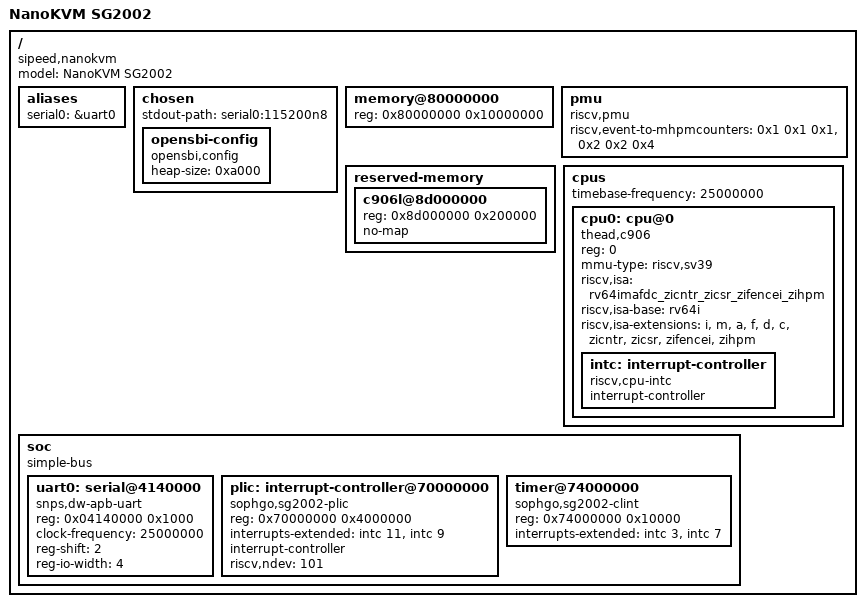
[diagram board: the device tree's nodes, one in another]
// SPDX-License-Identifier: (BSD-2-Clause OR MIT)
// M-mode hardware description: Linux 7.2.9 sg2002.dtsi/cv180x-cpus.dtsi
// and pinned Sipeed FSBL/UART data; independent of NanoKVM board wiring.
/dts-v1/;
/ {
	model = "NanoKVM SG2002";
	compatible = "sipeed,nanokvm", "sophgo,sg2002";
	#address-cells = <1>;
	#size-cells = <1>;
	aliases { serial0 = &uart0; };
	chosen {
		stdout-path = "serial0:115200n8";
		opensbi-config {
			compatible = "opensbi,config";
			heap-size = <0xa000>;
		};
	};
	memory@80000000 {
		device_type = "memory";
		reg = <0x80000000 0x10000000>;
	};
	pmu {
		compatible = "riscv,pmu";
		// SBI 3.0 event-info requires explicit fixed-counter mappings.
		// Advertise only the architectural mcycle/minstret events.
		riscv,event-to-mhpmcounters = <0x1 0x1 0x1>, <0x2 0x2 0x4>;
	};
	reserved-memory {
		#address-cells = <1>;
		#size-cells = <1>;
		ranges;
		c906l@8d000000 { reg = <0x8d000000 0x200000>; no-map; };
	};
	cpus {
		#address-cells = <1>;
		#size-cells = <0>;
		timebase-frequency = <25000000>;
		cpu0: cpu@0 {
			compatible = "thead,c906", "riscv";
			device_type = "cpu";
			reg = <0>;
			status = "okay";
			mmu-type = "riscv,sv39";
			// C906 draft vector support must never be declared as RVV 1.0.
			riscv,isa = "rv64imafdc_zicntr_zicsr_zifencei_zihpm";
			riscv,isa-base = "rv64i";
			riscv,isa-extensions = "i", "m", "a", "f", "d", "c",
				"zicntr", "zicsr", "zifencei", "zihpm";
			intc: interrupt-controller {
				compatible = "riscv,cpu-intc";
				interrupt-controller;
				#interrupt-cells = <1>;
			};
		};
	};
	soc {
		compatible = "simple-bus";
		#address-cells = <1>;
		#size-cells = <1>;
		ranges;
		uart0: serial@4140000 {
			compatible = "snps,dw-apb-uart";
			reg = <0x04140000 0x1000>;
			clock-frequency = <25000000>;
			reg-shift = <2>;
			reg-io-width = <4>;
		};
		plic: interrupt-controller@70000000 {
			compatible = "sophgo,sg2002-plic", "thead,c900-plic";
			reg = <0x70000000 0x4000000>;
			interrupts-extended = <&intc 11>, <&intc 9>;
			interrupt-controller;
			#address-cells = <0>;
			#interrupt-cells = <2>;
			riscv,ndev = <101>;
		};
		timer@74000000 {
			compatible = "sophgo,sg2002-clint", "thead,c900-clint";
			reg = <0x74000000 0x10000>;
			interrupts-extended = <&intc 3>, <&intc 7>;
		};
	};
};
